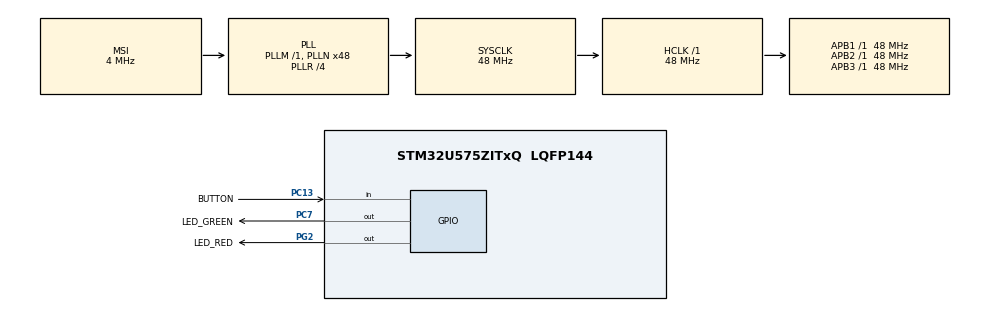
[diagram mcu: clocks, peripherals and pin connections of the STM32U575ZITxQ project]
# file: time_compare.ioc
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CORTEX_M33_NS.userName=CORTEX_M33
Mcu.Family=STM32U5
Mcu.Name=STM32U575ZITxQ
Mcu.Package=LQFP144
NVIC.PriorityGroup=NVIC_PRIORITYGROUP_4
PC13.GPIO_Label=BUTTON
PC13.Signal=GPIO_Input
PC14-OSC32_IN\ (PC14).Mode=LSE-External-Oscillator
PC14-OSC32_IN\ (PC14).Signal=RCC_OSC32_IN
PC15-OSC32_OUT\ (PC15).Mode=LSE-External-Oscillator
PC15-OSC32_OUT\ (PC15).Signal=RCC_OSC32_OUT
PC7.GPIO_Label=LED_GREEN
PC7.Signal=GPIO_Output
PG2.GPIO_Label=LED_RED
PG2.Signal=GPIO_Output
PWR.PowerMode=PWR_SMPS_SUPPLY
ProjectManager.HeapSize=0x200
ProjectManager.StackSize=0x400
ProjectManager.TargetToolchain=STM32CubeIDE
RCC.ADCFreq_Value=16000000
RCC.AHBFreq_Value=48000000
RCC.APB1Freq_Value=48000000
RCC.APB1TimFreq_Value=48000000
RCC.APB2Freq_Value=48000000
RCC.APB2TimFreq_Value=48000000
RCC.APB3Freq_Value=48000000
RCC.CortexFreq_Value=48000000
RCC.EPOD_VALUE=4000000
RCC.HCLKFreq_Value=48000000
RCC.HSE_VALUE=16000000
RCC.HSI48_VALUE=48000000
RCC.HSI_VALUE=16000000
RCC.LSIDIV_VALUE=32000
RCC.MSIAutoCalibration=PLLMODE_MSIS
RCC.MSI_VALUE=4000000
RCC.PLL1R=4
RCC.PLLN=48
RCC.SYSCLKFreq_VALUE=48000000
RCC.SYSCLKSource=RCC_SYSCLKSOURCE_PLLCLK
RCC.USBFreq_Value=48000000
RCC.VCOOutputFreq_Value=192000000
VP_ICACHE_VS_ICACHE.Mode=DirectMappedCache
VP_LPBAMQUEUE_VS_QUEUE.Mode=QUEUEMODE
VP_LPBAM_VS_SIG1.Mode=SmartRun
VP_LPBAM_VS_SIG4.Mode=LPDMA1
VP_MEMORYMAP_VS_MEMORYMAP.Mode=CurAppReg
VP_PWR_VS_LPOM.Mode=PowerOptimisation
VP_PWR_VS_SECSignals.Mode=Security/Privilege
board=custom

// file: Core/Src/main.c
/* USER CODE BEGIN Header */
/**
  ******************************************************************************
  * @file           : main.c
  * @brief          : Main program body
  ******************************************************************************
  * @attention
  *
  * Copyright (c) 2025 STMicroelectronics.
  * All rights reserved.
  *
  * This software is licensed under terms that can be found in the LICENSE file
  * in the root directory of this software component.
  * If no LICENSE file comes with this software, it is provided AS-IS.
  *
  ******************************************************************************
  */
/* USER CODE END Header */
#include "main.h"

void SystemClock_Config(void);
static void SystemPower_Config(void);
static void MX_GPIO_Init(void);
static void MX_ICACHE_Init(void);

int main(void)
{

  /* USER CODE BEGIN 1 */
  const uint32_t PERIOD_LED_RED = 500U;
  uint32_t last_time_led_red = 0U;
  const uint32_t PERIOD_LED_GREEN = 800U;
  uint32_t last_time_led_green = 0U;
  /* USER CODE END 1 */

  /* MCU Configuration--------------------------------------------------------*/

  /* Reset of all peripherals, Initializes the Flash interface and the Systick. */
  HAL_Init();

  /* Configure the System Power */
  SystemPower_Config();

  /* Configure the system clock */
  SystemClock_Config();

  /* Initialize all configured peripherals */
  MX_GPIO_Init();
  MX_ICACHE_Init();

  /* Infinite loop */
  /* USER CODE BEGIN WHILE */
  while (1)
  {
	uint32_t current_time = HAL_GetTick();
	if (current_time - last_time_led_red > PERIOD_LED_RED) {
		HAL_GPIO_TogglePin(LED_RED_GPIO_Port, LED_RED_Pin);
		last_time_led_red = current_time;
	}

	if (current_time - last_time_led_green > PERIOD_LED_GREEN) {
		HAL_GPIO_TogglePin(LED_GREEN_GPIO_Port, LED_GREEN_Pin);
		last_time_led_green = current_time;
	}

    /* USER CODE END WHILE */

  }
}

void SystemClock_Config(void)
{
  RCC_OscInitTypeDef RCC_OscInitStruct = {0};
  RCC_ClkInitTypeDef RCC_ClkInitStruct = {0};

  /** Configure the main internal regulator output voltage
  */
  if (HAL_PWREx_ControlVoltageScaling(PWR_REGULATOR_VOLTAGE_SCALE3) != HAL_OK)
  {
    Error_Handler();
  }

  /** Configure LSE Drive Capability
  */
  HAL_PWR_EnableBkUpAccess();
  __HAL_RCC_LSEDRIVE_CONFIG(RCC_LSEDRIVE_LOW);

  /** Initializes the CPU, AHB and APB buses clocks
  */
  RCC_OscInitStruct.OscillatorType = RCC_OSCILLATORTYPE_LSE|RCC_OSCILLATORTYPE_MSI;
  RCC_OscInitStruct.LSEState = RCC_LSE_ON;
  RCC_OscInitStruct.MSIState = RCC_MSI_ON;
  RCC_OscInitStruct.MSICalibrationValue = RCC_MSICALIBRATION_DEFAULT;
  RCC_OscInitStruct.MSIClockRange = RCC_MSIRANGE_4;
  RCC_OscInitStruct.PLL.PLLState = RCC_PLL_ON;
  RCC_OscInitStruct.PLL.PLLSource = RCC_PLLSOURCE_MSI;
  RCC_OscInitStruct.PLL.PLLMBOOST = RCC_PLLMBOOST_DIV1;
  RCC_OscInitStruct.PLL.PLLM = 1;
  RCC_OscInitStruct.PLL.PLLN = 48;
  RCC_OscInitStruct.PLL.PLLP = 2;
  RCC_OscInitStruct.PLL.PLLQ = 2;
  RCC_OscInitStruct.PLL.PLLR = 4;
  RCC_OscInitStruct.PLL.PLLRGE = RCC_PLLVCIRANGE_0;
  RCC_OscInitStruct.PLL.PLLFRACN = 0;
  if (HAL_RCC_OscConfig(&RCC_OscInitStruct) != HAL_OK)
  {
    Error_Handler();
  }

  /** Initializes the CPU, AHB and APB buses clocks
  */
  RCC_ClkInitStruct.ClockType = RCC_CLOCKTYPE_HCLK|RCC_CLOCKTYPE_SYSCLK
                              |RCC_CLOCKTYPE_PCLK1|RCC_CLOCKTYPE_PCLK2
                              |RCC_CLOCKTYPE_PCLK3;
  RCC_ClkInitStruct.SYSCLKSource = RCC_SYSCLKSOURCE_PLLCLK;
  RCC_ClkInitStruct.AHBCLKDivider = RCC_SYSCLK_DIV1;
  RCC_ClkInitStruct.APB1CLKDivider = RCC_HCLK_DIV1;
  RCC_ClkInitStruct.APB2CLKDivider = RCC_HCLK_DIV1;
  RCC_ClkInitStruct.APB3CLKDivider = RCC_HCLK_DIV1;

  if (HAL_RCC_ClockConfig(&RCC_ClkInitStruct, FLASH_LATENCY_1) != HAL_OK)
  {
    Error_Handler();
  }

  /** Enable MSI Auto calibration
  */
  HAL_RCCEx_EnableMSIPLLModeSelection(RCC_MSISPLL_MODE_SEL);
  HAL_RCCEx_EnableMSIPLLMode();
}

/**
  * @brief Power Configuration
  * @retval None
  */
static void SystemPower_Config(void)
{
  HAL_PWREx_EnableVddIO2();

  /*
   * Switch to SMPS regulator instead of LDO
   */
  if (HAL_PWREx_ConfigSupply(PWR_SMPS_SUPPLY) != HAL_OK)
  {
    Error_Handler();
  }
}

static void MX_ICACHE_Init(void)
{

  /** Enable instruction cache in 1-way (direct mapped cache)
  */
  if (HAL_ICACHE_ConfigAssociativityMode(ICACHE_1WAY) != HAL_OK)
  {
    Error_Handler();
  }
  if (HAL_ICACHE_Enable() != HAL_OK)
  {
    Error_Handler();
  }

}

static void MX_GPIO_Init(void)
{
  GPIO_InitTypeDef GPIO_InitStruct = {0};

  /* GPIO Ports Clock Enable */
  __HAL_RCC_GPIOC_CLK_ENABLE();
  __HAL_RCC_GPIOG_CLK_ENABLE();

  /*Configure GPIO pin Output Level */
  HAL_GPIO_WritePin(LED_RED_GPIO_Port, LED_RED_Pin, GPIO_PIN_RESET);

  /*Configure GPIO pin Output Level */
  HAL_GPIO_WritePin(LED_GREEN_GPIO_Port, LED_GREEN_Pin, GPIO_PIN_RESET);

  /*Configure GPIO pin : BUTTON_Pin */
  GPIO_InitStruct.Pin = BUTTON_Pin;
  GPIO_InitStruct.Mode = GPIO_MODE_INPUT;
  GPIO_InitStruct.Pull = GPIO_NOPULL;
  HAL_GPIO_Init(BUTTON_GPIO_Port, &GPIO_InitStruct);

  /*Configure GPIO pin : LED_RED_Pin */
  GPIO_InitStruct.Pin = LED_RED_Pin;
  GPIO_InitStruct.Mode = GPIO_MODE_OUTPUT_PP;
  GPIO_InitStruct.Pull = GPIO_NOPULL;
  GPIO_InitStruct.Speed = GPIO_SPEED_FREQ_LOW;
  HAL_GPIO_Init(LED_RED_GPIO_Port, &GPIO_InitStruct);

  /*Configure GPIO pin : LED_GREEN_Pin */
  GPIO_InitStruct.Pin = LED_GREEN_Pin;
  GPIO_InitStruct.Mode = GPIO_MODE_OUTPUT_PP;
  GPIO_InitStruct.Pull = GPIO_NOPULL;
  GPIO_InitStruct.Speed = GPIO_SPEED_FREQ_LOW;
  HAL_GPIO_Init(LED_GREEN_GPIO_Port, &GPIO_InitStruct);

}

void Error_Handler(void)
{
  __disable_irq();
  while (1)
  {
  }
}
